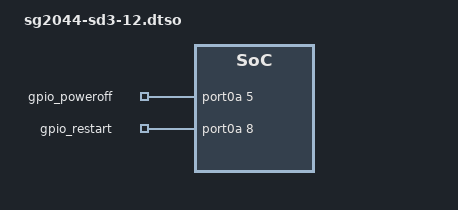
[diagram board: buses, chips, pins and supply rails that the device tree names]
/dts-v1/;
/plugin/;

&port0a {

	gpio_poweroff: gpio-poweroff {
		compatible = "gpio-poweroff";
		gpios = <&port0a 5 0>;
		active-delay-ms = <300>;
		inactive-delay-ms = <300>;
	};

	gpio_restart: gpio-restart {
		compatible = "gpio-restart";
		gpios = <&port0a 8 0>;
		active-delay-ms = <300>;
		inactive-delay-ms = <300>;
	};
};
